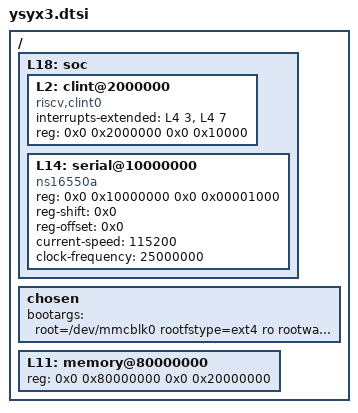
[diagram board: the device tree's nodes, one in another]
/dts-v1/;

/ {
	L18: soc {
		L2: clint@2000000 {
			compatible = "riscv,clint0";
			interrupts-extended = <&L4 3 &L4 7>;
			reg = <0x0 0x2000000 0x0 0x10000>;
		};
		L14: serial@10000000 {
			compatible = "ns16550a";
            reg = <0x0 0x10000000 0x0 0x00001000>;
            reg-shift = <0x0>;
            reg-offset = <0x0>;
            current-speed = <115200>;
            clock-frequency = <25000000>;
		};
	};
    chosen {
        //bootargs = "console=/dev/hvc0 root=/dev/mmcblk0 rootfstype=ext4 ro rootwait earlycon=sbi"; // for linux 5.0
        bootargs = "root=/dev/mmcblk0 rootfstype=ext4 ro rootwait earlycon";
    };
	L11: memory@80000000 {
		device_type = "memory";
		reg = <0x0 0x80000000 0x0 0x20000000>;
	};
};
